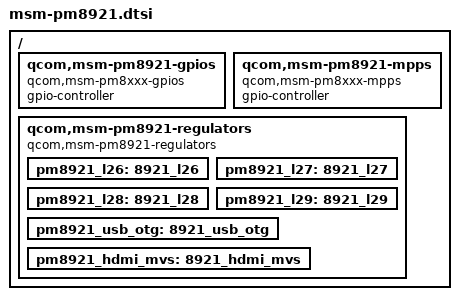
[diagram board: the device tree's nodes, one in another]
/* Copyright (c) 2012, Motorola Mobility LLC. All rights reserved.
 *
 * This program is free software; you can redistribute it and/or modify
 * it under the terms of the GNU General Public License version 2 and
 * only version 2 as published by the Free Software Foundation.
 *
 * This program is distributed in the hope that it will be useful,
 * but WITHOUT ANY WARRANTY; without even the implied warranty of
 * MERCHANTABILITY or FITNESS FOR A PARTICULAR PURPOSE.  See the
 * GNU General Public License for more details.
 */

/ {
	qcom,msm-pm8921-gpios {
		compatible = "qcom,msm-pm8xxx-gpios";
		gpio-controller;
		#gpio-cells = <2>;
	};

	qcom,msm-pm8921-mpps {
		compatible = "qcom,msm-pm8xxx-mpps";
		gpio-controller;
		#gpio-cells = <2>;
	};

	qcom,msm-pm8921-regulators {
		compatible = "qcom,msm-pm8921-regulators";

		pm8921_l26: 8921_l26 {
			status = "okay";
		};
		pm8921_l27: 8921_l27 {
			status = "okay";
		};
		pm8921_l28: 8921_l28 {
			status = "okay";
		};
		pm8921_l29: 8921_l29 {
			status = "okay";
		};

		pm8921_usb_otg: 8921_usb_otg {
			status = "okay";
		};
		pm8921_hdmi_mvs: 8921_hdmi_mvs {
			status = "okay";
		};
	};
};
